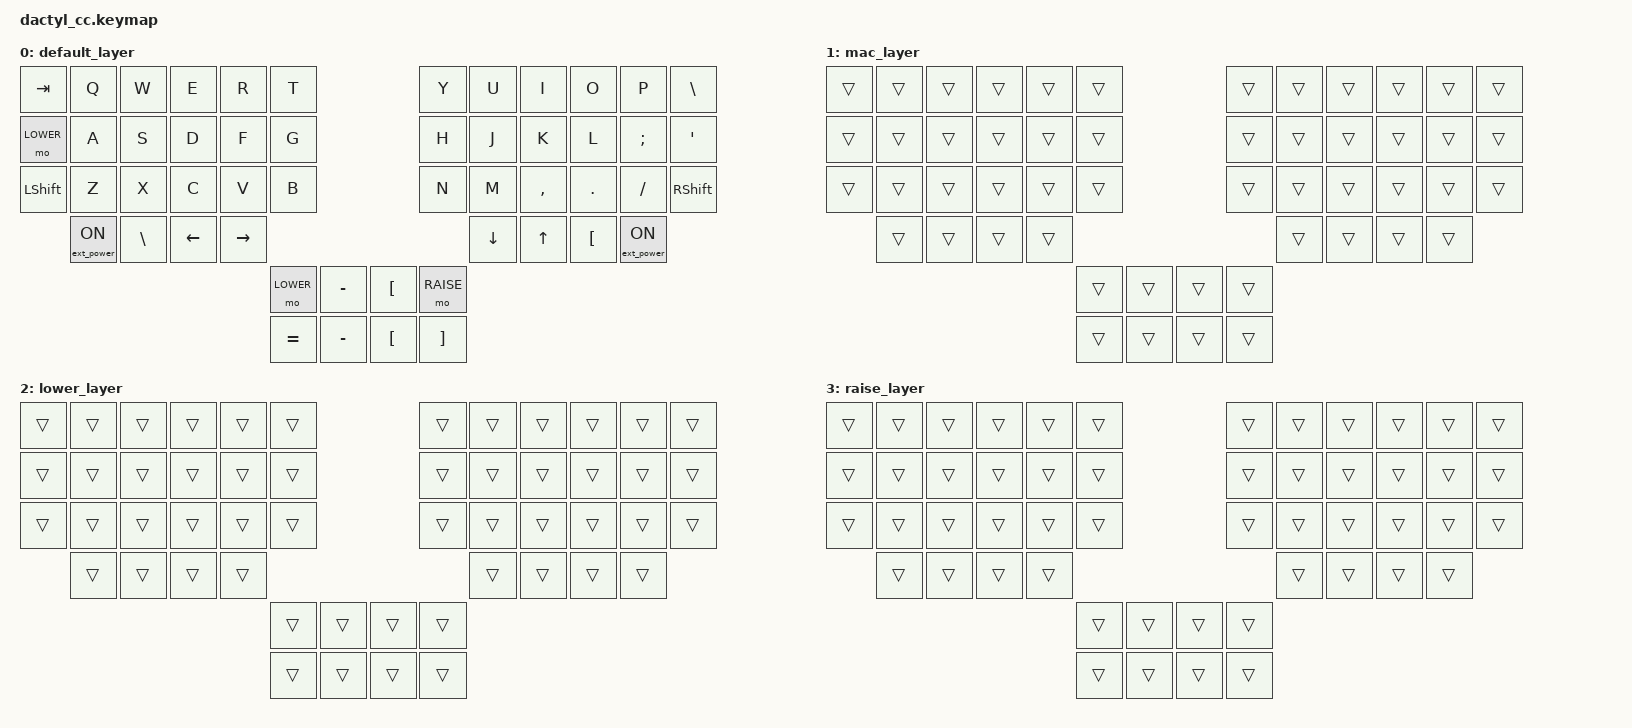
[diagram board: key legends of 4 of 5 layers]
#include <behaviors.dtsi>
#include <dt-bindings/zmk/keys.h>
#include <dt-bindings/zmk/bt.h>
#include <dt-bindings/zmk/outputs.h>
#include <dt-bindings/zmk/ext_power.h>


#define DEFAULT 0
#define MAC     1
#define LOWER   2
#define RAISE   3
#define ADJUST  4

#define HYPER(key) LS(LC(LA(LG(key))))
#define MEH(key)   LS(LC(LA(key)))

&sl {
    release-after-ms = <5000>;
};

&kscan0 {
    debounce-period = <25>;
};

/ {
    conditional_layers {
    compatible = "zmk,conditional-layers";

    tri_layer {
        if-layers = <LOWER RAISE>;
        then-layer = <ADJUST>;
    };
    };


    keymap {
        compatible = "zmk,keymap";

        default_layer {
            bindings = <
    &kp TAB   &kp Q     &kp W    &kp E     &kp R     &kp T                              &kp Y     &kp U     &kp I     &kp O     &kp P    &kp BSLH
    &mo LOWER &kp A     &kp S    &kp D     &kp F     &kp G                              &kp H     &kp J     &kp K     &kp L     &kp SEMI &kp SQT
    &kp LSHFT &kp Z     &kp X    &kp C     &kp V     &kp B                              &kp N     &kp M     &kp COMMA &kp DOT   &kp FSLH &kp RSHFT
              &ext_power EP_ON &kp BSLH &kp LEFT  &kp RIGHT                                       &kp DOWN  &kp UP    &kp LBKT  &ext_power EP_ON
                                                      &mo LOWER &kp MINUS   &kp LBKT  &mo RAISE
                                                      &kp EQUAL &kp MINUS   &kp LBKT  &kp RBKT
            >;
        };

        mac_layer {
            bindings = <
&trans   &trans     &trans     &trans     &trans     &trans                     &trans     &trans    &trans    &trans    &trans   &trans
&trans   &trans     &trans     &trans     &trans     &trans                     &trans     &trans    &trans    &trans    &trans   &trans
&trans   &trans     &trans     &trans     &trans     &trans                     &trans     &trans    &trans    &trans    &trans   &trans
         &trans     &trans     &trans     &trans                                           &trans    &trans    &trans    &trans
                                                     &trans  &trans     &trans  &trans
                                                     &trans  &trans     &trans  &trans
            >;
        };

        lower_layer {
            bindings = <
&trans   &trans     &trans     &trans     &trans     &trans                     &trans     &trans    &trans    &trans    &trans   &trans
&trans   &trans     &trans     &trans     &trans     &trans                     &trans     &trans    &trans    &trans    &trans   &trans
&trans   &trans     &trans     &trans     &trans     &trans                     &trans     &trans    &trans    &trans    &trans   &trans
         &trans     &trans     &trans     &trans                                           &trans    &trans    &trans    &trans
                                                     &trans  &trans     &trans  &trans
                                                     &trans  &trans     &trans  &trans
            >;
        };

        raise_layer {
            bindings = <
&trans   &trans     &trans     &trans     &trans     &trans                     &trans     &trans    &trans    &trans    &trans   &trans
&trans   &trans     &trans     &trans     &trans     &trans                     &trans     &trans    &trans    &trans    &trans   &trans
&trans   &trans     &trans     &trans     &trans     &trans                     &trans     &trans    &trans    &trans    &trans   &trans
         &trans     &trans     &trans     &trans                                           &trans    &trans    &trans    &trans
                                                     &trans  &trans     &trans  &trans
                                                     &trans  &trans     &trans  &trans
            >;
        };

        adjust_layer {
            bindings = <
    &none     &bt BT_SEL 0 &bt BT_SEL 1 &bt BT_SEL 2 &bt BT_SEL 3 &bt BT_SEL 4                         &none       &none     &none     &none     &none    &none
    &trans    &out OUT_USB &out OUT_BLE &none        &reset       &tog MAC                             &none       &reset    &none     &none     &none    &none
    &trans    &none        &none        &none        &none        &none                                &none       &none     &none     &none     &none    &none
    &none     &none        &bt BT_CLR   &none        &none        &bootloader                          &bootloader &none     &none     &none     &none    &none
                                                     &trans  &trans     &trans  &trans
                                                     &trans  &trans     &trans  &trans
            >;
        };
    };
};
